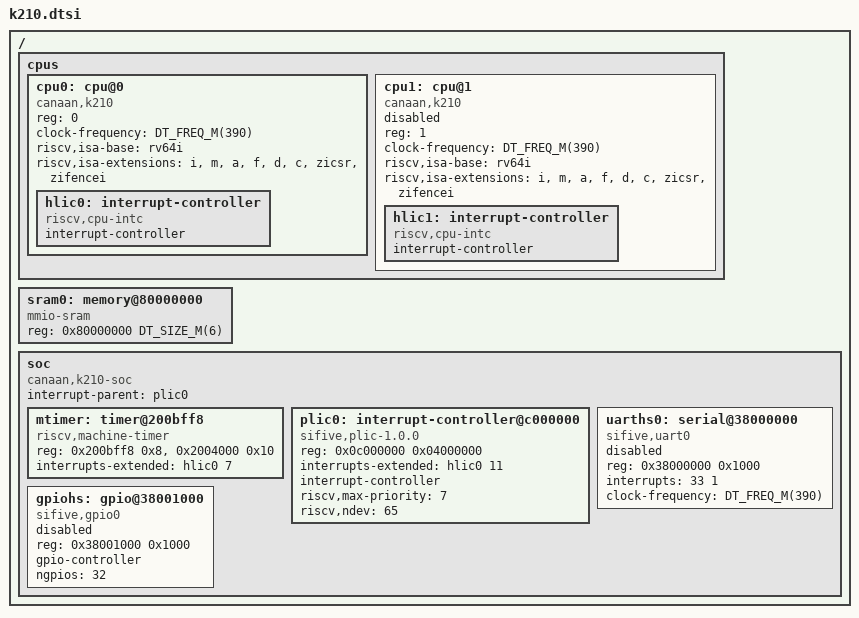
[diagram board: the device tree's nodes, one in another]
/*
 * Canaan Kendryte K210: 2x RV64GC @ 390 MHz (privileged spec 1.9.1, no MMU/PMP used),
 * 6 MiB general SRAM at 0x80000000 (+2 MiB AI SRAM at 0x80600000).
 * Facts from Linux k210.dtsi (removed upstream in 6.x): CLINT 0x02000000 (SiFive layout,
 * timebase = CPU/50 = 7.8 MHz), PLIC 0x0C000000 (65 sources), UARTHS 0x38000000
 * (SiFive UART layout, clocked from the CPU clock), GPIOHS 0x38001000 (SiFive GPIO,
 * needs FPIOA pin muxing: not described here).
 * SPDX-License-Identifier: Apache-2.0
 */

#include <mem.h>
#include <freq.h>

/ {
	#address-cells = <1>;
	#size-cells = <1>;

	cpus {
		#address-cells = <1>;
		#size-cells = <0>;

		cpu0: cpu@0 {
			compatible = "canaan,k210", "riscv";
			device_type = "cpu";
			reg = <0>;
			clock-frequency = <DT_FREQ_M(390)>;
			riscv,isa-base = "rv64i";
			riscv,isa-extensions = "i", "m", "a", "f", "d", "c", "zicsr", "zifencei";

			hlic0: interrupt-controller {
				compatible = "riscv,cpu-intc";
				#address-cells = <0>;
				#interrupt-cells = <1>;
				interrupt-controller;
			};
		};

		cpu1: cpu@1 {
			compatible = "canaan,k210", "riscv";
			device_type = "cpu";
			reg = <1>;
			clock-frequency = <DT_FREQ_M(390)>;
			riscv,isa-base = "rv64i";
			riscv,isa-extensions = "i", "m", "a", "f", "d", "c", "zicsr", "zifencei";
			status = "disabled";

			hlic1: interrupt-controller {
				compatible = "riscv,cpu-intc";
				#address-cells = <0>;
				#interrupt-cells = <1>;
				interrupt-controller;
			};
		};
	};

	sram0: memory@80000000 {
		compatible = "mmio-sram";
		reg = <0x80000000 DT_SIZE_M(6)>;
	};

	soc {
		compatible = "canaan,k210-soc", "simple-bus";
		#address-cells = <1>;
		#size-cells = <1>;
		interrupt-parent = <&plic0>;
		ranges;

		mtimer: timer@200bff8 {
			compatible = "riscv,machine-timer";
			reg = <0x200bff8 0x8>, <0x2004000 0x10>;
			reg-names = "mtime", "mtimecmp";
			interrupts-extended = <&hlic0 7>;
		};

		plic0: interrupt-controller@c000000 {
			compatible = "sifive,plic-1.0.0";
			reg = <0x0c000000 0x04000000>;
			interrupts-extended = <&hlic0 11>;
			interrupt-controller;
			riscv,max-priority = <7>;
			riscv,ndev = <65>;
			#address-cells = <0>;
			#interrupt-cells = <2>;
		};

		uarths0: serial@38000000 {
			compatible = "sifive,uart0";
			reg = <0x38000000 0x1000>;
			interrupts = <33 1>;
			clock-frequency = <DT_FREQ_M(390)>;
			status = "disabled";
		};

		gpiohs: gpio@38001000 {
			compatible = "sifive,gpio0";
			reg = <0x38001000 0x1000>;
			gpio-controller;
			#gpio-cells = <2>;
			ngpios = <32>;
			status = "disabled";
		};
	};
};
